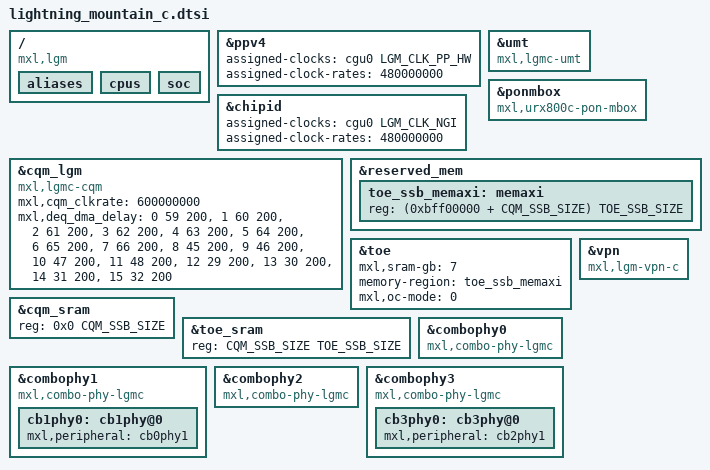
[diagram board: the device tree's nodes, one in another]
// SPDX-License-Identifier: GPL-2.0
/*
 * Copyright (C) 2023 - 2024 MaxLinear, Inc.
 */

#define LGMC_SOC
#include "lightning_mountain.dtsi"

/{
	compatible = "mxl,lgm", "intel,lgm", "mxl,lgmc";

	aliases {
		/delete-property/ usb0;
		/delete-property/ cpu2;
		/delete-property/ cpu3;
	};

	cpus {
		/delete-node/ cpu@8;
		/delete-node/ cpu@a;
	};

	soc {
		/delete-node/ usb@0;
		/delete-node/ sata@d1a00000;
		/delete-node/ sata@d1b00000;
		/delete-node/ sata@c1a00000;
		/delete-node/ sata@c1b00000;
	};
};

&ppv4 {
	assigned-clocks = <&cgu0 LGM_CLK_PP_HW>;
	assigned-clock-rates = <480000000>;
};

&chipid {
	assigned-clocks = <&cgu0 LGM_CLK_NGI>;
	assigned-clock-rates = <480000000>;
};

#define CQM_SSB_SIZE (0x28000)
#define TOE_SSB_SIZE (0x80000 - CQM_SSB_SIZE)

&cqm_lgm {
	compatible = "mxl,lgmc-cqm";
	mxl,cqm_clkrate = <600000000>;
	mxl,deq_dma_delay = <0 59 200>, /* DCP0  - DOCSIS FIFO 0 */
			    <1 60 200>, /* DCP1  - DOCSIS FIFO 1 */
			    <2 61 200>, /* DCP2  - DOCSIS FIFO 2 */
			    <3 62 200>, /* DCP3  - DOCSIS FIFO 3 */
			    <4 63 200>, /* DCP4  - DOCSIS FIFO 4 */
			    <5 64 200>, /* DCP5  - DOCSIS FIFO 5 */
			    <6 65 200>, /* DCP6  - DOCSIS FIFO 6 */
			    <7 66 200>, /* DCP7  - DOCSIS FIFO 7 */
			    <8 45 200>, /* DCP8  - FSQM Q4 */
			    <9 46 200>, /* DCP9  - FSQM Q5 */
			    <10 47 200>, /* DCP10 - FSQM Q6 */
			    <11 48 200>, /* DCP11 - FSQM Q7 */
			    <12 29 200>, /* DCP12 - FSQM Q0 */
			    <13 30 200>, /* DCP13 - FSQM Q1 */
			    <14 31 200>, /* DCP14 - FSQM Q2 */
			    <15 32 200>; /* DCP15 - FSQM Q3 */
};

&umt {
	compatible = "mxl,lgmc-umt";
};

&ponmbox {
	compatible = "mxl,urx800c-pon-mbox";
};

&reserved_mem {
	toe_ssb_memaxi: memaxi {
		reg = <(0xbff00000 + CQM_SSB_SIZE) TOE_SSB_SIZE>;
	};
};

&toe {
	mxl,sram-gb = <7>;
	memory-region = <&toe_ssb_memaxi>;
	mxl,oc-mode = <0>;
};

&cqm_sram {
	reg = <0x0 CQM_SSB_SIZE>;
};

&toe_sram {
	reg = <CQM_SSB_SIZE TOE_SSB_SIZE>;
};

&combophy0 {
	compatible = "mxl,combo-phy-lgmc", "simple-bus";
};

&combophy1 {
	compatible = "mxl,combo-phy-lgmc", "simple-bus";
	cb1phy0:cb1phy@0 {
		mxl,peripheral = <&cb0phy1>; /* This property must be deleted to configure to pcie mode, default mode is C10PHY mode*/
	};
};

&combophy2 {
	compatible = "mxl,combo-phy-lgmc", "simple-bus";
};

&combophy3 {
	compatible = "mxl,combo-phy-lgmc", "simple-bus";
	cb3phy0:cb3phy@0 {
		mxl,peripheral = <&cb2phy1>; /* This property must be deleted to configure to pcie mode, default mode is C10PHY mode*/

	};
};

&vpn {
	compatible = "mxl,lgm-vpn-c";
};

